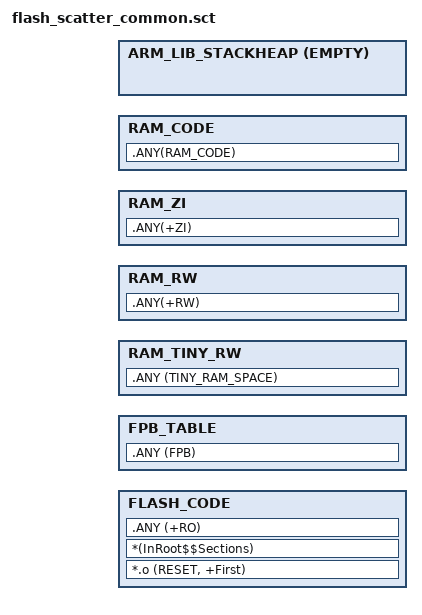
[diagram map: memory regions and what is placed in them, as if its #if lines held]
#! armcc -E -I ..\Src\config\ -I .\..\Src\user\ --cpu Cortex-M4

#include "flash_scatter_config.h"
#define ALIGN_DWORD 0x0008
#define ALIGN_WORD  0x0004
#define ALIGN_16KB  0x4000
#define ALIGN_32KB  0x8000

; *************************************************************
; *** Scatter-Loading Description File generated by uVision ***
; *************************************************************
;
; If an application uses a different memory layout then it must
; use a customized scatter file.
;**************************************************************

LR_FLASH APP_CODE_RUN_ADDR FLASH_SIZE {

    ; Flash layout
    FLASH_CODE APP_CODE_RUN_ADDR APP_MAX_CODE_SIZE {  ; load address = execution address
        *.o (RESET, +First)
        *(InRoot$$Sections)
        .ANY (+RO)
    }

    ; RAM for fpb resource
    FPB_TABLE FPB_SECTION_START FPB_SECTION_SIZE {
        .ANY (FPB)
    }
  
    ; RAM Layout
    #if defined(USE_TINY_RAM_SPACE)
    RAM_TINY_RW TINY_RAM_SPACE_START TINY_RAM_SPACE_SIZE {
        .ANY (TINY_RAM_SPACE)
    }
    #endif

    ; RAM for Application code
    RAM_RW (RAM_START_ADDR + ROM_RTN_RAM_SIZE) APP_RAM_SIZE {
        .ANY(+RW)
    }
    RAM_ZI +0 APP_RAM_SIZE {
        .ANY(+ZI)
    }

    #if defined(XIP_MODE)
    ; retention RAM for exflash driver code
    RAM_CODE AlignExpr(+0, ALIGN_WORD) CRITICAL_CODE_MAX_SIZE {
        .ANY(RAM_CODE)
    }
    #endif

    ; define call-stack space
    ARM_LIB_STACKHEAP AlignExpr(STACK_END_ADDR, ALIGN_DWORD) EMPTY -CSTACK_HEAP_SIZE {}
}
